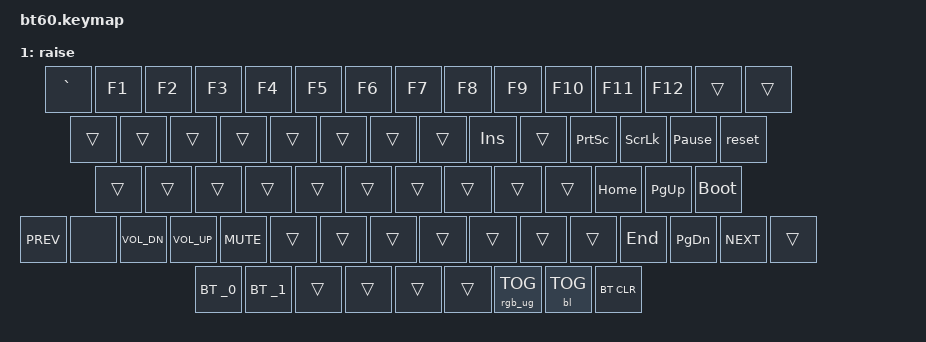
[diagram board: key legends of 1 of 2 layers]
#include <behaviors.dtsi>
#include <dt-bindings/zmk/keys.h>
#include <dt-bindings/zmk/bt.h>
#include <dt-bindings/zmk/rgb.h>
#include <dt-bindings/zmk/backlight.h>

/ {
	macros {
		plus: plus {
			label = "ZM_plus";
			compatible = "zmk,behavior-macro";
			#binding-cells = <0>;
			bindings
				= <&macro_press &kp LCTRL>
				, <&macro_tap &kp PLUS>
				, <&macro_release &kp LCTRL>
				;
		minus: minus {
			label = "ZM_minus";
			compatible = "zmk,behavior-macro";
			#binding-cells = <0>;
			bindings
				= <&macro_press &kp LCTRL>
				, <&macro_tap &kp MINUS>
				, <&macro_release &kp LCTRL>
				;
		};
	keymap {
		compatible = "zmk,keymap";

		default_layer {
				// ------------------------------------------------------------------------------------------
				// | ESC |  1  |  2  |  3  |  4  |  5  |  6  |  7  |  8  |  9  |  0  |  -  |  =  |BKSP | DEL |
				// | TAB  |  Q  |  W  |  E  |  R  |  T  |  Y  |  U  |  I  |  O  |  P  |  [  |  ]  |  |   |
				// | CAPS  |  A  |  S  |  D  |  F  |  G  |  H  |  J  |  K  |  L  |  ;  |  '  |     ENTER    |
				// |  SHIFT|NONE|  Z  |  X  |  C  |  V  |  B  |  N  |  M  |  ,  |  .  | /   | SHFT | UP | 1  |
				// |  CTL  |  WIN  |  ALT  |            SPACE              | ALT | CTRL | LEFT | DOWN | RIGHT |
				// ------------------------------------------------------------------------------------------
			bindings = <
				&kp ESC &kp N1 &kp N2 &kp N3 &kp N4 &kp N5 &kp N6 &kp N7 &kp  N8   &kp  N9 &kp  N0  &kp MINUS &kp EQUAL &kp BSPC &kp PAUSE_BREAK
				&kp TAB  &kp Q  &kp W  &kp E  &kp R  &kp T  &kp Y  &kp U  &kp  I    &kp  O  &kp  P   &kp LBKT &kp RBKT  &kp BSLH
				&kp CLCK  &kp A  &kp S  &kp D  &kp F  &kp G  &kp H  &kp J  &kp  K    &kp  L  &kp SEMI &kp SQT           &kp RET
				&kp LSHFT &none  &kp Z  &kp X  &kp C  &kp V  &kp B  &kp N  &kp M  &kp COMMA &kp DOT &mt(RSHFT,FSLH)    &mt(RSHFT,FSLH) &kp UP   &mo 1
				&kp LCTRL &kp LGUI &kp LALT            &kp SPACE                          &kp RALT  &mo 1 &kp LEFT &kp DOWN &kp RIGHT
			>;
			sensor-bindings = <&inc_dec_kp <&plus> <&minus>;
		};
		raise {
			bindings = <
				&kp GRAVE &kp F1 &kp F2 &kp F3 &kp F4 &kp F5 &kp F6 &kp F7 &kp  F8   &kp  F9 &kp  F10  &kp F11 &kp F12   &trans &trans
				&trans &trans &trans &trans &trans &trans &trans &trans &kp INS &trans &kp PSCRN &kp SLCK &kp PAUSE_BREAK &reset
				&trans    &trans &trans &trans &trans &trans &trans &trans &trans &trans &kp HOME  &kp PG_UP   &bootloader
				&kp C_PREV &none &kp C_VOL_DN &kp C_VOL_UP &kp C_MUTE &trans &trans &trans &trans &trans &trans &trans &kp END &kp PG_DN  &kp C_NEXT &trans
				&bt BT_SEL_0 &bt BT_SEL_1  &trans              &trans                            &trans  &trans &rgb_ug RGB_TOG   &bl BL_TOG &bt BT_CLR
			>;
			sensor-bindings = <&inc_dec_kp C_VOL_UP C_VOL_DN>;
		};
	};
};
